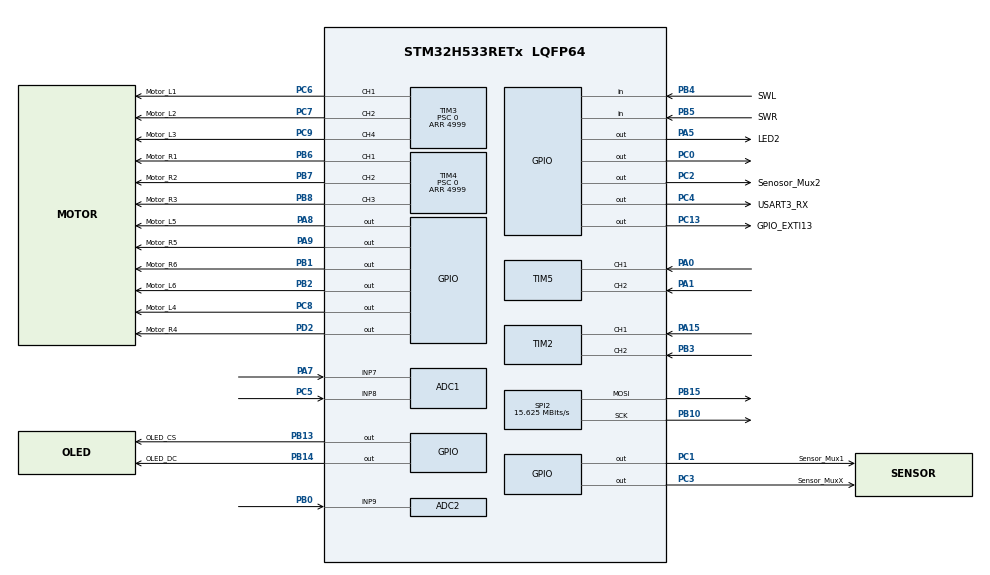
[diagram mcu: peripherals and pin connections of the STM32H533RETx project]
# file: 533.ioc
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ADC1.Channel-0\#ChannelRegularConversion=ADC_CHANNEL_7
ADC1.Channel-1\#ChannelRegularConversion=ADC_CHANNEL_7
ADC1.Channel-2\#ChannelRegularConversion=ADC_CHANNEL_8
ADC1.DiscontinuousConvMode=ENABLE
ADC1.MonitoredBy-0\#ChannelRegularConversion=__NULL
ADC1.MonitoredBy-1\#ChannelRegularConversion=__NULL
ADC1.MonitoredBy-2\#ChannelRegularConversion=__NULL
ADC1.NbrOfConversion=3
ADC1.NbrOfConversionFlag=1
ADC1.NbrOfDiscConversion=1
ADC1.OffsetNumber-0\#ChannelRegularConversion=ADC_OFFSET_NONE
ADC1.OffsetNumber-1\#ChannelRegularConversion=ADC_OFFSET_NONE
ADC1.OffsetNumber-2\#ChannelRegularConversion=ADC_OFFSET_NONE
ADC1.Overrun=ADC_OVR_DATA_OVERWRITTEN
ADC1.Rank-0\#ChannelRegularConversion=1
ADC1.Rank-1\#ChannelRegularConversion=2
ADC1.Rank-2\#ChannelRegularConversion=3
ADC1.SamplingTime-0\#ChannelRegularConversion=ADC_SAMPLETIME_2CYCLES_5
ADC1.SamplingTime-1\#ChannelRegularConversion=ADC_SAMPLETIME_2CYCLES_5
ADC1.SamplingTime-2\#ChannelRegularConversion=ADC_SAMPLETIME_2CYCLES_5
ADC1.master=1
ADC2.Channel-0\#ChannelRegularConversion=ADC_CHANNEL_9
ADC2.MonitoredBy-0\#ChannelRegularConversion=__NULL
ADC2.NbrOfConversionFlag=1
ADC2.OffsetNumber-0\#ChannelRegularConversion=ADC_OFFSET_NONE
ADC2.Rank-0\#ChannelRegularConversion=1
ADC2.SamplingTime-0\#ChannelRegularConversion=ADC_SAMPLETIME_2CYCLES_5
BOOTPATH.BootPathName=LEGACY
BOOTPATH.UserSelectedBootPath=LEGACY
CORTEX_M33_NS.userName=CORTEX_M33
FLASH.OB_EDATA1_active=false
FLASH.advanced_settings=false
Mcu.Family=STM32H5
Mcu.Name=STM32H533RETx
Mcu.Package=LQFP64
NVIC.PriorityGroup=NVIC_PRIORITYGROUP_4
NVIC.TIM3_IRQn=true\:0\:0\:false\:false\:true\:true\:true\:true
NVIC.TIM4_IRQn=true\:0\:0\:false\:false\:true\:true\:true\:true
NVIC.TIM6_IRQn=true\:0\:0\:false\:false\:true\:true\:true\:true
NVIC.TIM7_IRQn=true\:0\:0\:false\:false\:true\:true\:true\:true
PA0.Signal=S_TIM5_CH1
PA1.Signal=S_TIM5_CH2
PA15(JTDI).Signal=S_TIM2_CH1
PA5.GPIO_Label=LED2
PA5.Signal=GPIO_Output
PA7.Signal=ADCx_INP7
PA8.GPIO_Label=Motor_L5
PA8.Signal=GPIO_Output
PA9.GPIO_Label=Motor_R5
PA9.Signal=GPIO_Output
PB0.Signal=ADCx_INP9
PB1.GPIO_Label=Motor_R6
PB1.Signal=GPIO_Output
PB10.Mode=TX_Only_Simplex_Unidirect_Master
PB10.Signal=SPI2_SCK
PB13.GPIO_Label=OLED_CS
PB13.Signal=GPIO_Output
PB14.GPIO_Label=OLED_DC
PB14.Signal=GPIO_Output
PB15.Mode=TX_Only_Simplex_Unidirect_Master
PB15.Signal=SPI2_MOSI
PB2.GPIO_Label=Motor_L6
PB2.Signal=GPIO_Output
PB3(JTDO/TRACESWO).Signal=S_TIM2_CH2
PB4(NJTRST).GPIO_Label=SWL
PB4(NJTRST).GPIO_PuPd=GPIO_PULLUP
PB4(NJTRST).Signal=GPIO_Input
PB5.GPIO_Label=SWR
PB5.GPIO_PuPd=GPIO_PULLUP
PB5.Signal=GPIO_Input
PB6.GPIO_Label=Motor_R1
PB6.Signal=S_TIM4_CH1
PB7.GPIO_Label=Motor_R2
PB7.Signal=S_TIM4_CH2
PB8.GPIO_Label=Motor_R3
PB8.Signal=S_TIM4_CH3
PC0.Signal=GPIO_Output
PC1.GPIO_Label=Sensor_Mux1
PC1.Signal=GPIO_Output
PC13.GPIO_Label=GPIO_EXTI13
PC13.Signal=GPIO_Output
PC14-OSC32_IN(OSC32_IN).Mode=LSE-External-Oscillator
PC14-OSC32_IN(OSC32_IN).Signal=RCC_OSC32_IN
PC15-OSC32_OUT(OSC32_OUT).Mode=LSE-External-Oscillator
PC15-OSC32_OUT(OSC32_OUT).Signal=RCC_OSC32_OUT
PC2.GPIO_Label=Senosor_Mux2
PC2.Signal=GPIO_Output
PC3.GPIO_Label=Sensor_MuxX
PC3.Signal=GPIO_Output
PC4.GPIO_Label=USART3_RX
PC4.Signal=GPIO_Output
PC5.Signal=ADCx_INP8
PC6.GPIO_Label=Motor_L1
PC6.Signal=S_TIM3_CH1
PC7.GPIO_Label=Motor_L2
PC7.Signal=S_TIM3_CH2
PC8.GPIO_Label=Motor_L4
PC8.Signal=GPIO_Output
PC9.GPIO_Label=Motor_L3
PC9.Signal=S_TIM3_CH4
PD2.GPIO_Label=Motor_R4
PD2.Signal=GPIO_Output
PH0-OSC_IN(PH0).Mode=HSE-External-Oscillator
PH0-OSC_IN(PH0).Signal=RCC_OSC_IN
PH1-OSC_OUT(PH1).Mode=HSE-External-Oscillator
PH1-OSC_OUT(PH1).Signal=RCC_OSC_OUT
ProjectManager.HeapSize=0x200
ProjectManager.StackSize=0x400
ProjectManager.TargetToolchain=STM32CubeIDE
RCC.ADCCLockSelection=RCC_ADCDACCLKSOURCE_HSE
RCC.ADCFreq_Value=25000000
RCC.AHBFreq_Value=250000000
RCC.APB1Freq_Value=250000000
RCC.APB1TimFreq_Value=250000000
RCC.APB2Freq_Value=250000000
RCC.APB2TimFreq_Value=250000000
RCC.APB3Freq_Value=250000000
RCC.CSI_VALUE=4000000
RCC.CortexFreq_Value=250000000
RCC.EPOD_VALUE=4000000
RCC.HCLKFreq_Value=250000000
RCC.HSE_VALUE=25000000
RCC.HSI48_VALUE=48000000
RCC.HSI_VALUE=64000000
RCC.LSIRC_VALUE=32000
RCC.PLLFRACN=0
RCC.PLLN=125
RCC.SYSCLKFreq_VALUE=250000000
RCC.SYSCLKSource=RCC_SYSCLKSOURCE_PLLCLK
RCC.USBFreq_Value=48000000
RCC.VCOOutputFreq_Value=500000000
SH.ADCx_INP7.0=ADC1_INP7,IN7-Single-Ended
SH.ADCx_INP8.0=ADC1_INP8,IN8-Single-Ended
SH.ADCx_INP9.0=ADC2_INP9,IN9-Single-Ended
SH.S_TIM2_CH1.0=TIM2_CH1,Encoder_Interface
SH.S_TIM2_CH2.0=TIM2_CH2,Encoder_Interface
SH.S_TIM3_CH1.0=TIM3_CH1,PWM Generation1 CH1
SH.S_TIM3_CH2.0=TIM3_CH2,PWM Generation2 CH2
SH.S_TIM3_CH4.0=TIM3_CH4,PWM Generation4 CH4
SH.S_TIM4_CH1.0=TIM4_CH1,PWM Generation1 CH1
SH.S_TIM4_CH2.0=TIM4_CH2,PWM Generation2 CH2
SH.S_TIM4_CH3.0=TIM4_CH3,PWM Generation3 CH3
SH.S_TIM5_CH1.0=TIM5_CH1,Encoder_Interface
SH.S_TIM5_CH2.0=TIM5_CH2,Encoder_Interface
SPI2.BaudRatePrescaler=SPI_BAUDRATEPRESCALER_16
SPI2.CalculateBaudRate=15.625 MBits/s
SPI2.DataSize=SPI_DATASIZE_8BIT
SPI2.Direction=SPI_DIRECTION_2LINES_TXONLY
SPI2.Mode=SPI_MODE_MASTER
SPI2.VirtualType=VM_MASTER
TIM1.Prescaler=249
TIM3.Channel-PWM\ Generation1\ CH1=TIM_CHANNEL_1
TIM3.Channel-PWM\ Generation2\ CH2=TIM_CHANNEL_2
TIM3.Channel-PWM\ Generation4\ CH4=TIM_CHANNEL_4
TIM3.PeriodNoDither=4999
TIM3.Prescaler=0
TIM4.Channel-PWM\ Generation1\ CH1=TIM_CHANNEL_1
TIM4.Channel-PWM\ Generation2\ CH2=TIM_CHANNEL_2
TIM4.Channel-PWM\ Generation3\ CH3=TIM_CHANNEL_3
TIM4.PeriodNoDither=4999
TIM4.Prescaler=0
TIM6.PeriodNoDither=7999
TIM7.PeriodNoDither=499
TIM7.Prescaler=249
VP_BOOTPATH_VS_BOOTPATH.Mode=BP_Activate
VP_CORTEX_M33_NS_VS_Hclk.Mode=Hclk_Mode
VP_FLASH_SIG_Activate_FlashIP.Mode=Activate_FlashIP
VP_ICACHE_VS_ICACHE.Mode=DefaultMode
VP_MEMORYMAP_VS_MEMORYMAP.Mode=CurAppReg
VP_PWR_VS_DBSignals.Mode=DisableDeadBatterySignals
VP_PWR_VS_LPOM.Mode=PowerOptimisation
VP_PWR_VS_SECSignals.Mode=Security/Privilege
VP_TIM1_VS_ClockSourceINT.Mode=Internal
VP_TIM3_VS_ClockSourceINT.Mode=Internal
VP_TIM4_VS_ClockSourceINT.Mode=Internal
VP_TIM6_VS_ClockSourceINT.Mode=Enable_Timer
VP_TIM7_VS_ClockSourceINT.Mode=Enable_Timer
board=custom

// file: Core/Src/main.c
/* USER CODE BEGIN Header */
/**
  ******************************************************************************
  * @file           : main.c
  * @brief          : Main program body
  ******************************************************************************
  * @attention
  *
  * Copyright (c) 2025 STMicroelectronics.
  * All rights reserved.
  *
  * This software is licensed under terms that can be found in the LICENSE file
  * in the root directory of this software component.
  * If no LICENSE file comes with this software, it is provided AS-IS.
  *
  ******************************************************************************
  */
/* USER CODE END Header */
#include "main.h"

/* USER CODE BEGIN Includes */
#include "init.h"

/* USER CODE END Includes */

void SystemClock_Config(void);
static void MX_GPIO_Init(void);
static void MX_TIM1_Init(void);
static void MX_TIM6_Init(void);
static void MX_TIM3_Init(void);
static void MX_TIM4_Init(void);
static void MX_TIM2_Init(void);
static void MX_TIM5_Init(void);
static void MX_TIM7_Init(void);
static void MX_ADC1_Init(void);
static void MX_ADC2_Init(void);
static void MX_SPI2_Init(void);
static void MX_ICACHE_Init(void);
static void MX_FLASH_Init(void);

int main(void)
{

  /* MCU Configuration--------------------------------------------------------*/

  /* Reset of all peripherals, Initializes the Flash interface and the Systick. */
  HAL_Init();

  /** Disable the internal Pull-Up in Dead Battery pins of UCPD peripheral
  */
  LL_PWR_DisableUCPDDeadBattery();

  /* Configure the system clock */
  SystemClock_Config();

  /* Initialize all configured peripherals */
  MX_GPIO_Init();
  MX_TIM1_Init();
  MX_TIM6_Init();
  MX_TIM3_Init();
  MX_TIM4_Init();
  MX_TIM2_Init();
  MX_TIM5_Init();
  MX_TIM7_Init();
  MX_ADC1_Init();
  MX_ADC2_Init();
  MX_SPI2_Init();
  MX_ICACHE_Init();
  MX_FLASH_Init();

  /* Infinite loop */
  while (1)
  {

    /* USER CODE BEGIN 3 */
	  Init();
  }
  /* USER CODE END 3 */
}

void SystemClock_Config(void)
{
  LL_FLASH_SetLatency(LL_FLASH_LATENCY_5);
  while(LL_FLASH_GetLatency()!= LL_FLASH_LATENCY_5)
  {
  }

  LL_PWR_SetRegulVoltageScaling(LL_PWR_REGU_VOLTAGE_SCALE0);
  while (LL_PWR_IsActiveFlag_VOS() == 0)
  {
  }
  LL_RCC_HSE_Enable();

   /* Wait till HSE is ready */
  while(LL_RCC_HSE_IsReady() != 1)
  {
  }

  LL_RCC_CSI_Enable();

   /* Wait till CSI is ready */
  while(LL_RCC_CSI_IsReady() != 1)
  {
  }

  LL_RCC_CSI_SetCalibTrimming(32);
  LL_RCC_PLL1_SetSource(LL_RCC_PLL1SOURCE_CSI);
  LL_RCC_PLL1_SetVCOInputRange(LL_RCC_PLLINPUTRANGE_4_8);
  LL_RCC_PLL1_SetVCOOutputRange(LL_RCC_PLLVCORANGE_WIDE);
  LL_RCC_PLL1_SetM(1);
  LL_RCC_PLL1_SetN(125);
  LL_RCC_PLL1_SetP(2);
  LL_RCC_PLL1_SetQ(2);
  LL_RCC_PLL1_SetR(2);
  LL_RCC_PLL1Q_Enable();
  LL_RCC_PLL1P_Enable();
  LL_RCC_PLL1_Enable();

   /* Wait till PLL is ready */
  while(LL_RCC_PLL1_IsReady() != 1)
  {
  }

  LL_RCC_SetSysClkSource(LL_RCC_SYS_CLKSOURCE_PLL1);

   /* Wait till System clock is ready */
  while(LL_RCC_GetSysClkSource() != LL_RCC_SYS_CLKSOURCE_STATUS_PLL1)
  {
  }

  LL_RCC_SetAHBPrescaler(LL_RCC_SYSCLK_DIV_1);
  LL_RCC_SetAPB1Prescaler(LL_RCC_APB1_DIV_1);
  LL_RCC_SetAPB2Prescaler(LL_RCC_APB2_DIV_1);
  LL_RCC_SetAPB3Prescaler(LL_RCC_APB3_DIV_1);
  LL_SetSystemCoreClock(250000000);

   /* Update the time base */
  if (HAL_InitTick (TICK_INT_PRIORITY) != HAL_OK)
  {
    Error_Handler();
  }
}

static void MX_ADC1_Init(void)
{

  LL_ADC_CommonInitTypeDef ADC_CommonInitStruct = {0};
  LL_ADC_InitTypeDef ADC_InitStruct = {0};
  LL_ADC_REG_InitTypeDef ADC_REG_InitStruct = {0};

  LL_GPIO_InitTypeDef GPIO_InitStruct = {0};

  LL_RCC_SetADCDACClockSource(LL_RCC_ADCDAC_CLKSOURCE_HSE);

  /* Peripheral clock enable */
  LL_AHB2_GRP1_EnableClock(LL_AHB2_GRP1_PERIPH_ADC);

  LL_AHB2_GRP1_EnableClock(LL_AHB2_GRP1_PERIPH_GPIOA);
  LL_AHB2_GRP1_EnableClock(LL_AHB2_GRP1_PERIPH_GPIOC);
  /**ADC1 GPIO Configuration
  PA7   ------> ADC1_INP7
  PC5   ------> ADC1_INP8
  */
  GPIO_InitStruct.Pin = LL_GPIO_PIN_7;
  GPIO_InitStruct.Mode = LL_GPIO_MODE_ANALOG;
  GPIO_InitStruct.Pull = LL_GPIO_PULL_NO;
  LL_GPIO_Init(GPIOA, &GPIO_InitStruct);

  GPIO_InitStruct.Pin = LL_GPIO_PIN_5;
  GPIO_InitStruct.Mode = LL_GPIO_MODE_ANALOG;
  GPIO_InitStruct.Pull = LL_GPIO_PULL_NO;
  LL_GPIO_Init(GPIOC, &GPIO_InitStruct);

  /** Configure the ADC multi-mode
  */
  ADC_CommonInitStruct.CommonClock = LL_ADC_CLOCK_ASYNC_DIV1;
  ADC_CommonInitStruct.Multimode = LL_ADC_MULTI_INDEPENDENT;
  LL_ADC_CommonInit(__LL_ADC_COMMON_INSTANCE(ADC1), &ADC_CommonInitStruct);

  /** Common config
  */
  ADC_InitStruct.Resolution = LL_ADC_RESOLUTION_12B;
  ADC_InitStruct.DataAlignment = LL_ADC_DATA_ALIGN_RIGHT;
  ADC_InitStruct.LowPowerMode = LL_ADC_LP_MODE_NONE;
  LL_ADC_Init(ADC1, &ADC_InitStruct);
  ADC_REG_InitStruct.TriggerSource = LL_ADC_REG_TRIG_SOFTWARE;
  ADC_REG_InitStruct.SequencerLength = LL_ADC_REG_SEQ_SCAN_ENABLE_3RANKS;
  ADC_REG_InitStruct.SequencerDiscont = LL_ADC_REG_SEQ_DISCONT_1RANK;
  ADC_REG_InitStruct.ContinuousMode = LL_ADC_REG_CONV_SINGLE;
  ADC_REG_InitStruct.Overrun = LL_ADC_REG_OVR_DATA_OVERWRITTEN;
  LL_ADC_REG_Init(ADC1, &ADC_REG_InitStruct);
  LL_ADC_REG_SetSamplingMode(ADC1, LL_ADC_REG_SAMPLING_MODE_NORMAL);

  /* Disable ADC deep power down (enabled by default after reset state) */
  LL_ADC_DisableDeepPowerDown(ADC1);
  /* Enable ADC internal voltage regulator */
  LL_ADC_EnableInternalRegulator(ADC1);
  /* Delay for ADC internal voltage regulator stabilization. */
  /* Compute number of CPU cycles to wait for, from delay in us. */
  /* Note: Variable divided by 2 to compensate partially */
  /* CPU processing cycles (depends on compilation optimization). */
  /* Note: If system core clock frequency is below 200kHz, wait time */
  /* is only a few CPU processing cycles. */
  uint32_t wait_loop_index;
  wait_loop_index = ((LL_ADC_DELAY_INTERNAL_REGUL_STAB_US * (SystemCoreClock / (100000 * 2))) / 10);
  while(wait_loop_index != 0)
  {
    wait_loop_index--;
  }

  /** Configure Regular Channel
  */
  LL_ADC_REG_SetSequencerRanks(ADC1, LL_ADC_REG_RANK_1, LL_ADC_CHANNEL_7);
  LL_ADC_SetChannelSamplingTime(ADC1, LL_ADC_CHANNEL_7, LL_ADC_SAMPLINGTIME_2CYCLES_5);
  LL_ADC_SetChannelSingleDiff(ADC1, LL_ADC_CHANNEL_7, LL_ADC_SINGLE_ENDED);

  /** Configure Regular Channel
  */
  LL_ADC_REG_SetSequencerRanks(ADC1, LL_ADC_REG_RANK_2, LL_ADC_CHANNEL_7);
  LL_ADC_SetChannelSamplingTime(ADC1, LL_ADC_CHANNEL_7, LL_ADC_SAMPLINGTIME_2CYCLES_5);
  LL_ADC_SetChannelSingleDiff(ADC1, LL_ADC_CHANNEL_7, LL_ADC_SINGLE_ENDED);

  /** Configure Regular Channel
  */
  LL_ADC_REG_SetSequencerRanks(ADC1, LL_ADC_REG_RANK_3, LL_ADC_CHANNEL_8);
  LL_ADC_SetChannelSamplingTime(ADC1, LL_ADC_CHANNEL_8, LL_ADC_SAMPLINGTIME_2CYCLES_5);
  LL_ADC_SetChannelSingleDiff(ADC1, LL_ADC_CHANNEL_8, LL_ADC_SINGLE_ENDED);

}

static void MX_ADC2_Init(void)
{

  LL_ADC_CommonInitTypeDef ADC_CommonInitStruct = {0};
  LL_ADC_InitTypeDef ADC_InitStruct = {0};
  LL_ADC_REG_InitTypeDef ADC_REG_InitStruct = {0};

  LL_GPIO_InitTypeDef GPIO_InitStruct = {0};

  LL_RCC_SetADCDACClockSource(LL_RCC_ADCDAC_CLKSOURCE_HSE);

  /* Peripheral clock enable */
  LL_AHB2_GRP1_EnableClock(LL_AHB2_GRP1_PERIPH_ADC);

  LL_AHB2_GRP1_EnableClock(LL_AHB2_GRP1_PERIPH_GPIOB);
  /**ADC2 GPIO Configuration
  PB0   ------> ADC2_INP9
  */
  GPIO_InitStruct.Pin = LL_GPIO_PIN_0;
  GPIO_InitStruct.Mode = LL_GPIO_MODE_ANALOG;
  GPIO_InitStruct.Pull = LL_GPIO_PULL_NO;
  LL_GPIO_Init(GPIOB, &GPIO_InitStruct);

  /** Configure the ADC multi-mode
  */
  ADC_CommonInitStruct.CommonClock = LL_ADC_CLOCK_ASYNC_DIV1;
  ADC_CommonInitStruct.Multimode = LL_ADC_MULTI_INDEPENDENT;
  LL_ADC_CommonInit(__LL_ADC_COMMON_INSTANCE(ADC2), &ADC_CommonInitStruct);

  /** Common config
  */
  ADC_InitStruct.Resolution = LL_ADC_RESOLUTION_12B;
  ADC_InitStruct.DataAlignment = LL_ADC_DATA_ALIGN_RIGHT;
  ADC_InitStruct.LowPowerMode = LL_ADC_LP_MODE_NONE;
  LL_ADC_Init(ADC2, &ADC_InitStruct);
  ADC_REG_InitStruct.TriggerSource = LL_ADC_REG_TRIG_SOFTWARE;
  ADC_REG_InitStruct.SequencerLength = LL_ADC_REG_SEQ_SCAN_DISABLE;
  ADC_REG_InitStruct.SequencerDiscont = LL_ADC_REG_SEQ_DISCONT_DISABLE;
  ADC_REG_InitStruct.ContinuousMode = LL_ADC_REG_CONV_SINGLE;
  ADC_REG_InitStruct.Overrun = LL_ADC_REG_OVR_DATA_PRESERVED;
  LL_ADC_REG_Init(ADC2, &ADC_REG_InitStruct);
  LL_ADC_REG_SetSamplingMode(ADC2, LL_ADC_REG_SAMPLING_MODE_NORMAL);

  /* Disable ADC deep power down (enabled by default after reset state) */
  LL_ADC_DisableDeepPowerDown(ADC2);
  /* Enable ADC internal voltage regulator */
  LL_ADC_EnableInternalRegulator(ADC2);
  /* Delay for ADC internal voltage regulator stabilization. */
  /* Compute number of CPU cycles to wait for, from delay in us. */
  /* Note: Variable divided by 2 to compensate partially */
  /* CPU processing cycles (depends on compilation optimization). */
  /* Note: If system core clock frequency is below 200kHz, wait time */
  /* is only a few CPU processing cycles. */
  uint32_t wait_loop_index;
  wait_loop_index = ((LL_ADC_DELAY_INTERNAL_REGUL_STAB_US * (SystemCoreClock / (100000 * 2))) / 10);
  while(wait_loop_index != 0)
  {
    wait_loop_index--;
  }

  /** Configure Regular Channel
  */
  LL_ADC_REG_SetSequencerRanks(ADC2, LL_ADC_REG_RANK_1, LL_ADC_CHANNEL_9);
  LL_ADC_SetChannelSamplingTime(ADC2, LL_ADC_CHANNEL_9, LL_ADC_SAMPLINGTIME_2CYCLES_5);
  LL_ADC_SetChannelSingleDiff(ADC2, LL_ADC_CHANNEL_9, LL_ADC_SINGLE_ENDED);

}

static void MX_FLASH_Init(void)
{

  if (HAL_FLASH_Unlock() != HAL_OK)
  {
    Error_Handler();
  }
  if (HAL_FLASH_Lock() != HAL_OK)
  {
    Error_Handler();
  }

}

static void MX_ICACHE_Init(void)
{

  /** Enable instruction cache (default 2-ways set associative cache)
  */
  LL_ICACHE_Enable();

}

static void MX_SPI2_Init(void)
{

  LL_SPI_InitTypeDef SPI_InitStruct = {0};

  LL_GPIO_InitTypeDef GPIO_InitStruct = {0};

  LL_RCC_SetSPIClockSource(LL_RCC_SPI2_CLKSOURCE_PLL1Q);

  /* Peripheral clock enable */
  LL_APB1_GRP1_EnableClock(LL_APB1_GRP1_PERIPH_SPI2);

  LL_AHB2_GRP1_EnableClock(LL_AHB2_GRP1_PERIPH_GPIOB);
  /**SPI2 GPIO Configuration
  PB10   ------> SPI2_SCK
  PB15   ------> SPI2_MOSI
  */
  GPIO_InitStruct.Pin = LL_GPIO_PIN_10|LL_GPIO_PIN_15;
  GPIO_InitStruct.Mode = LL_GPIO_MODE_ALTERNATE;
  GPIO_InitStruct.Speed = LL_GPIO_SPEED_FREQ_LOW;
  GPIO_InitStruct.OutputType = LL_GPIO_OUTPUT_PUSHPULL;
  GPIO_InitStruct.Pull = LL_GPIO_PULL_NO;
  GPIO_InitStruct.Alternate = LL_GPIO_AF_5;
  LL_GPIO_Init(GPIOB, &GPIO_InitStruct);

  /* SPI2 parameter configuration*/
  SPI_InitStruct.TransferDirection = LL_SPI_SIMPLEX_TX;
  SPI_InitStruct.Mode = LL_SPI_MODE_MASTER;
  SPI_InitStruct.DataWidth = LL_SPI_DATAWIDTH_8BIT;
  SPI_InitStruct.ClockPolarity = LL_SPI_POLARITY_LOW;
  SPI_InitStruct.ClockPhase = LL_SPI_PHASE_1EDGE;
  SPI_InitStruct.NSS = LL_SPI_NSS_SOFT;
  SPI_InitStruct.BaudRate = LL_SPI_BAUDRATEPRESCALER_DIV16;
  SPI_InitStruct.BitOrder = LL_SPI_MSB_FIRST;
  SPI_InitStruct.CRCCalculation = LL_SPI_CRCCALCULATION_DISABLE;
  SPI_InitStruct.CRCPoly = 0x7;
  LL_SPI_Init(SPI2, &SPI_InitStruct);
  LL_SPI_SetStandard(SPI2, LL_SPI_PROTOCOL_MOTOROLA);
  LL_SPI_EnableNSSPulseMgt(SPI2);

}

static void MX_TIM1_Init(void)
{

  LL_TIM_InitTypeDef TIM_InitStruct = {0};

  /* Peripheral clock enable */
  LL_APB2_GRP1_EnableClock(LL_APB2_GRP1_PERIPH_TIM1);

  TIM_InitStruct.Prescaler = 249;
  TIM_InitStruct.CounterMode = LL_TIM_COUNTERMODE_UP;
  TIM_InitStruct.Autoreload = 65535;
  TIM_InitStruct.ClockDivision = LL_TIM_CLOCKDIVISION_DIV1;
  TIM_InitStruct.RepetitionCounter = 0;
  LL_TIM_Init(TIM1, &TIM_InitStruct);
  LL_TIM_DisableARRPreload(TIM1);
  LL_TIM_SetClockSource(TIM1, LL_TIM_CLOCKSOURCE_INTERNAL);
  LL_TIM_SetTriggerOutput(TIM1, LL_TIM_TRGO_RESET);
  LL_TIM_SetTriggerOutput2(TIM1, LL_TIM_TRGO2_RESET);
  LL_TIM_DisableMasterSlaveMode(TIM1);

}

static void MX_TIM2_Init(void)
{

  LL_TIM_InitTypeDef TIM_InitStruct = {0};

  LL_GPIO_InitTypeDef GPIO_InitStruct = {0};

  /* Peripheral clock enable */
  LL_APB1_GRP1_EnableClock(LL_APB1_GRP1_PERIPH_TIM2);

  LL_AHB2_GRP1_EnableClock(LL_AHB2_GRP1_PERIPH_GPIOA);
  LL_AHB2_GRP1_EnableClock(LL_AHB2_GRP1_PERIPH_GPIOB);
  /**TIM2 GPIO Configuration
  PA15(JTDI)   ------> TIM2_CH1
  PB3(JTDO/TRACESWO)   ------> TIM2_CH2
  */
  GPIO_InitStruct.Pin = LL_GPIO_PIN_15;
  GPIO_InitStruct.Mode = LL_GPIO_MODE_ALTERNATE;
  GPIO_InitStruct.Speed = LL_GPIO_SPEED_FREQ_LOW;
  GPIO_InitStruct.OutputType = LL_GPIO_OUTPUT_PUSHPULL;
  GPIO_InitStruct.Pull = LL_GPIO_PULL_NO;
  GPIO_InitStruct.Alternate = LL_GPIO_AF_1;
  LL_GPIO_Init(GPIOA, &GPIO_InitStruct);

  GPIO_InitStruct.Pin = LL_GPIO_PIN_3;
  GPIO_InitStruct.Mode = LL_GPIO_MODE_ALTERNATE;
  GPIO_InitStruct.Speed = LL_GPIO_SPEED_FREQ_LOW;
  GPIO_InitStruct.OutputType = LL_GPIO_OUTPUT_PUSHPULL;
  GPIO_InitStruct.Pull = LL_GPIO_PULL_NO;
  GPIO_InitStruct.Alternate = LL_GPIO_AF_1;
  LL_GPIO_Init(GPIOB, &GPIO_InitStruct);

  TIM_InitStruct.Prescaler = 0;
  TIM_InitStruct.CounterMode = LL_TIM_COUNTERMODE_UP;
  TIM_InitStruct.Autoreload = 4294967295;
  TIM_InitStruct.ClockDivision = LL_TIM_CLOCKDIVISION_DIV1;
  LL_TIM_Init(TIM2, &TIM_InitStruct);
  LL_TIM_DisableARRPreload(TIM2);
  LL_TIM_SetEncoderMode(TIM2, LL_TIM_ENCODERMODE_X2_TI1);
  LL_TIM_IC_SetActiveInput(TIM2, LL_TIM_CHANNEL_CH1, LL_TIM_ACTIVEINPUT_DIRECTTI);
  LL_TIM_IC_SetPrescaler(TIM2, LL_TIM_CHANNEL_CH1, LL_TIM_ICPSC_DIV1);
  LL_TIM_IC_SetFilter(TIM2, LL_TIM_CHANNEL_CH1, LL_TIM_IC_FILTER_FDIV1);
  LL_TIM_IC_SetPolarity(TIM2, LL_TIM_CHANNEL_CH1, LL_TIM_IC_POLARITY_RISING);
  LL_TIM_IC_SetActiveInput(TIM2, LL_TIM_CHANNEL_CH2, LL_TIM_ACTIVEINPUT_DIRECTTI);
  LL_TIM_IC_SetPrescaler(TIM2, LL_TIM_CHANNEL_CH2, LL_TIM_ICPSC_DIV1);
  LL_TIM_IC_SetFilter(TIM2, LL_TIM_CHANNEL_CH2, LL_TIM_IC_FILTER_FDIV1);
  LL_TIM_IC_SetPolarity(TIM2, LL_TIM_CHANNEL_CH2, LL_TIM_IC_POLARITY_RISING);
  LL_TIM_SetTriggerOutput(TIM2, LL_TIM_TRGO_RESET);
  LL_TIM_DisableMasterSlaveMode(TIM2);

}

static void MX_TIM3_Init(void)
{

  LL_TIM_InitTypeDef TIM_InitStruct = {0};
  LL_TIM_OC_InitTypeDef TIM_OC_InitStruct = {0};

  LL_GPIO_InitTypeDef GPIO_InitStruct = {0};

  /* Peripheral clock enable */
  LL_APB1_GRP1_EnableClock(LL_APB1_GRP1_PERIPH_TIM3);

  /* TIM3 interrupt Init */
  NVIC_SetPriority(TIM3_IRQn, NVIC_EncodePriority(NVIC_GetPriorityGrouping(),0, 0));
  NVIC_EnableIRQ(TIM3_IRQn);

  TIM_InitStruct.Prescaler = 0;
  TIM_InitStruct.CounterMode = LL_TIM_COUNTERMODE_UP;
  TIM_InitStruct.Autoreload = 4999;
  TIM_InitStruct.ClockDivision = LL_TIM_CLOCKDIVISION_DIV1;
  LL_TIM_Init(TIM3, &TIM_InitStruct);
  LL_TIM_DisableARRPreload(TIM3);
  LL_TIM_SetClockSource(TIM3, LL_TIM_CLOCKSOURCE_INTERNAL);
  LL_TIM_OC_EnablePreload(TIM3, LL_TIM_CHANNEL_CH1);
  TIM_OC_InitStruct.OCMode = LL_TIM_OCMODE_PWM1;
  TIM_OC_InitStruct.OCState = LL_TIM_OCSTATE_DISABLE;
  TIM_OC_InitStruct.OCNState = LL_TIM_OCSTATE_DISABLE;
  TIM_OC_InitStruct.CompareValue = 0;
  TIM_OC_InitStruct.OCPolarity = LL_TIM_OCPOLARITY_HIGH;
  LL_TIM_OC_Init(TIM3, LL_TIM_CHANNEL_CH1, &TIM_OC_InitStruct);
  LL_TIM_OC_DisableFast(TIM3, LL_TIM_CHANNEL_CH1);
  LL_TIM_OC_EnablePreload(TIM3, LL_TIM_CHANNEL_CH2);
  LL_TIM_OC_Init(TIM3, LL_TIM_CHANNEL_CH2, &TIM_OC_InitStruct);
  LL_TIM_OC_DisableFast(TIM3, LL_TIM_CHANNEL_CH2);
  LL_TIM_OC_EnablePreload(TIM3, LL_TIM_CHANNEL_CH4);
  LL_TIM_OC_Init(TIM3, LL_TIM_CHANNEL_CH4, &TIM_OC_InitStruct);
  LL_TIM_OC_DisableFast(TIM3, LL_TIM_CHANNEL_CH4);
  LL_TIM_SetTriggerOutput(TIM3, LL_TIM_TRGO_RESET);
  LL_TIM_DisableMasterSlaveMode(TIM3);
  LL_AHB2_GRP1_EnableClock(LL_AHB2_GRP1_PERIPH_GPIOC);
  /**TIM3 GPIO Configuration
  PC6   ------> TIM3_CH1
  PC7   ------> TIM3_CH2
  PC9   ------> TIM3_CH4
  */
  GPIO_InitStruct.Pin = Motor_L1_Pin|Motor_L2_Pin|Motor_L3_Pin;
  GPIO_InitStruct.Mode = LL_GPIO_MODE_ALTERNATE;
  GPIO_InitStruct.Speed = LL_GPIO_SPEED_FREQ_LOW;
  GPIO_InitStruct.OutputType = LL_GPIO_OUTPUT_PUSHPULL;
  GPIO_InitStruct.Pull = LL_GPIO_PULL_NO;
  GPIO_InitStruct.Alternate = LL_GPIO_AF_2;
  LL_GPIO_Init(GPIOC, &GPIO_InitStruct);

}

static void MX_TIM4_Init(void)
{

  LL_TIM_InitTypeDef TIM_InitStruct = {0};
  LL_TIM_OC_InitTypeDef TIM_OC_InitStruct = {0};

  LL_GPIO_InitTypeDef GPIO_InitStruct = {0};

  /* Peripheral clock enable */
  LL_APB1_GRP1_EnableClock(LL_APB1_GRP1_PERIPH_TIM4);

  /* TIM4 interrupt Init */
  NVIC_SetPriority(TIM4_IRQn, NVIC_EncodePriority(NVIC_GetPriorityGrouping(),0, 0));
  NVIC_EnableIRQ(TIM4_IRQn);

  TIM_InitStruct.Prescaler = 0;
  TIM_InitStruct.CounterMode = LL_TIM_COUNTERMODE_UP;
  TIM_InitStruct.Autoreload = 4999;
  TIM_InitStruct.ClockDivision = LL_TIM_CLOCKDIVISION_DIV1;
  LL_TIM_Init(TIM4, &TIM_InitStruct);
  LL_TIM_DisableARRPreload(TIM4);
  LL_TIM_SetClockSource(TIM4, LL_TIM_CLOCKSOURCE_INTERNAL);
  LL_TIM_OC_EnablePreload(TIM4, LL_TIM_CHANNEL_CH1);
  TIM_OC_InitStruct.OCMode = LL_TIM_OCMODE_PWM1;
  TIM_OC_InitStruct.OCState = LL_TIM_OCSTATE_DISABLE;
  TIM_OC_InitStruct.OCNState = LL_TIM_OCSTATE_DISABLE;
  TIM_OC_InitStruct.CompareValue = 0;
  TIM_OC_InitStruct.OCPolarity = LL_TIM_OCPOLARITY_HIGH;
  LL_TIM_OC_Init(TIM4, LL_TIM_CHANNEL_CH1, &TIM_OC_InitStruct);
  LL_TIM_OC_DisableFast(TIM4, LL_TIM_CHANNEL_CH1);
  LL_TIM_OC_EnablePreload(TIM4, LL_TIM_CHANNEL_CH2);
  LL_TIM_OC_Init(TIM4, LL_TIM_CHANNEL_CH2, &TIM_OC_InitStruct);
  LL_TIM_OC_DisableFast(TIM4, LL_TIM_CHANNEL_CH2);
  LL_TIM_OC_EnablePreload(TIM4, LL_TIM_CHANNEL_CH3);
  LL_TIM_OC_Init(TIM4, LL_TIM_CHANNEL_CH3, &TIM_OC_InitStruct);
  LL_TIM_OC_DisableFast(TIM4, LL_TIM_CHANNEL_CH3);
  LL_TIM_SetTriggerOutput(TIM4, LL_TIM_TRGO_RESET);
  LL_TIM_DisableMasterSlaveMode(TIM4);
  LL_AHB2_GRP1_EnableClock(LL_AHB2_GRP1_PERIPH_GPIOB);
  /**TIM4 GPIO Configuration
  PB6   ------> TIM4_CH1
  PB7   ------> TIM4_CH2
  PB8   ------> TIM4_CH3
  */
  GPIO_InitStruct.Pin = Motor_R1_Pin|Motor_R2_Pin|Motor_R3_Pin;
  GPIO_InitStruct.Mode = LL_GPIO_MODE_ALTERNATE;
  GPIO_InitStruct.Speed = LL_GPIO_SPEED_FREQ_LOW;
  GPIO_InitStruct.OutputType = LL_GPIO_OUTPUT_PUSHPULL;
  GPIO_InitStruct.Pull = LL_GPIO_PULL_NO;
  GPIO_InitStruct.Alternate = LL_GPIO_AF_2;
  LL_GPIO_Init(GPIOB, &GPIO_InitStruct);

}

static void MX_TIM5_Init(void)
{

  LL_TIM_InitTypeDef TIM_InitStruct = {0};

  LL_GPIO_InitTypeDef GPIO_InitStruct = {0};

  /* Peripheral clock enable */
  LL_APB1_GRP1_EnableClock(LL_APB1_GRP1_PERIPH_TIM5);

  LL_AHB2_GRP1_EnableClock(LL_AHB2_GRP1_PERIPH_GPIOA);
  /**TIM5 GPIO Configuration
  PA0   ------> TIM5_CH1
  PA1   ------> TIM5_CH2
  */
  GPIO_InitStruct.Pin = LL_GPIO_PIN_0|LL_GPIO_PIN_1;
  GPIO_InitStruct.Mode = LL_GPIO_MODE_ALTERNATE;
  GPIO_InitStruct.Speed = LL_GPIO_SPEED_FREQ_LOW;
  GPIO_InitStruct.OutputType = LL_GPIO_OUTPUT_PUSHPULL;
  GPIO_InitStruct.Pull = LL_GPIO_PULL_NO;
  GPIO_InitStruct.Alternate = LL_GPIO_AF_2;
  LL_GPIO_Init(GPIOA, &GPIO_InitStruct);

  TIM_InitStruct.Prescaler = 0;
  TIM_InitStruct.CounterMode = LL_TIM_COUNTERMODE_UP;
  TIM_InitStruct.Autoreload = 4294967295;
  TIM_InitStruct.ClockDivision = LL_TIM_CLOCKDIVISION_DIV1;
  LL_TIM_Init(TIM5, &TIM_InitStruct);
  LL_TIM_DisableARRPreload(TIM5);
  LL_TIM_SetEncoderMode(TIM5, LL_TIM_ENCODERMODE_X2_TI1);
  LL_TIM_IC_SetActiveInput(TIM5, LL_TIM_CHANNEL_CH1, LL_TIM_ACTIVEINPUT_DIRECTTI);
  LL_TIM_IC_SetPrescaler(TIM5, LL_TIM_CHANNEL_CH1, LL_TIM_ICPSC_DIV1);
  LL_TIM_IC_SetFilter(TIM5, LL_TIM_CHANNEL_CH1, LL_TIM_IC_FILTER_FDIV1);
  LL_TIM_IC_SetPolarity(TIM5, LL_TIM_CHANNEL_CH1, LL_TIM_IC_POLARITY_RISING);
  LL_TIM_IC_SetActiveInput(TIM5, LL_TIM_CHANNEL_CH2, LL_TIM_ACTIVEINPUT_DIRECTTI);
  LL_TIM_IC_SetPrescaler(TIM5, LL_TIM_CHANNEL_CH2, LL_TIM_ICPSC_DIV1);
  LL_TIM_IC_SetFilter(TIM5, LL_TIM_CHANNEL_CH2, LL_TIM_IC_FILTER_FDIV1);
  LL_TIM_IC_SetPolarity(TIM5, LL_TIM_CHANNEL_CH2, LL_TIM_IC_POLARITY_RISING);
  LL_TIM_SetTriggerOutput(TIM5, LL_TIM_TRGO_RESET);
  LL_TIM_DisableMasterSlaveMode(TIM5);

}

static void MX_TIM6_Init(void)
{

  LL_TIM_InitTypeDef TIM_InitStruct = {0};

  /* Peripheral clock enable */
  LL_APB1_GRP1_EnableClock(LL_APB1_GRP1_PERIPH_TIM6);

  /* TIM6 interrupt Init */
  NVIC_SetPriority(TIM6_IRQn, NVIC_EncodePriority(NVIC_GetPriorityGrouping(),0, 0));
  NVIC_EnableIRQ(TIM6_IRQn);

  TIM_InitStruct.Prescaler = 0;
  TIM_InitStruct.CounterMode = LL_TIM_COUNTERMODE_UP;
  TIM_InitStruct.Autoreload = 7999;
  LL_TIM_Init(TIM6, &TIM_InitStruct);
  LL_TIM_DisableARRPreload(TIM6);
  LL_TIM_SetTriggerOutput(TIM6, LL_TIM_TRGO_RESET);
  LL_TIM_DisableMasterSlaveMode(TIM6);

}

static void MX_TIM7_Init(void)
{

  LL_TIM_InitTypeDef TIM_InitStruct = {0};

  /* Peripheral clock enable */
  LL_APB1_GRP1_EnableClock(LL_APB1_GRP1_PERIPH_TIM7);

  /* TIM7 interrupt Init */
  NVIC_SetPriority(TIM7_IRQn, NVIC_EncodePriority(NVIC_GetPriorityGrouping(),0, 0));
  NVIC_EnableIRQ(TIM7_IRQn);

  TIM_InitStruct.Prescaler = 249;
  TIM_InitStruct.CounterMode = LL_TIM_COUNTERMODE_UP;
  TIM_InitStruct.Autoreload = 499;
  LL_TIM_Init(TIM7, &TIM_InitStruct);
  LL_TIM_DisableARRPreload(TIM7);
  LL_TIM_SetTriggerOutput(TIM7, LL_TIM_TRGO_RESET);
  LL_TIM_DisableMasterSlaveMode(TIM7);

}

static void MX_GPIO_Init(void)
{
  LL_GPIO_InitTypeDef GPIO_InitStruct = {0};

  /* GPIO Ports Clock Enable */
  LL_AHB2_GRP1_EnableClock(LL_AHB2_GRP1_PERIPH_GPIOC);
  LL_AHB2_GRP1_EnableClock(LL_AHB2_GRP1_PERIPH_GPIOH);
  LL_AHB2_GRP1_EnableClock(LL_AHB2_GRP1_PERIPH_GPIOA);
  LL_AHB2_GRP1_EnableClock(LL_AHB2_GRP1_PERIPH_GPIOB);
  LL_AHB2_GRP1_EnableClock(LL_AHB2_GRP1_PERIPH_GPIOD);

  /**/
  LL_GPIO_ResetOutputPin(GPIOC, GPIO_EXTI13_Pin|LL_GPIO_PIN_0|Sensor_Mux1_Pin|Senosor_Mux2_Pin
                          |Sensor_MuxX_Pin|USART3_RX_Pin|Motor_L4_Pin);

  /**/
  LL_GPIO_ResetOutputPin(GPIOA, LED2_Pin|Motor_L5_Pin|Motor_R5_Pin);

  /**/
  LL_GPIO_ResetOutputPin(GPIOB, Motor_R6_Pin|Motor_L6_Pin|OLED_CS_Pin|OLED_DC_Pin);

  /**/
  LL_GPIO_ResetOutputPin(Motor_R4_GPIO_Port, Motor_R4_Pin);

  /**/
  GPIO_InitStruct.Pin = GPIO_EXTI13_Pin|LL_GPIO_PIN_0|Sensor_Mux1_Pin|Senosor_Mux2_Pin
                          |Sensor_MuxX_Pin|USART3_RX_Pin|Motor_L4_Pin;
  GPIO_InitStruct.Mode = LL_GPIO_MODE_OUTPUT;
  GPIO_InitStruct.Speed = LL_GPIO_SPEED_FREQ_LOW;
  GPIO_InitStruct.OutputType = LL_GPIO_OUTPUT_PUSHPULL;
  GPIO_InitStruct.Pull = LL_GPIO_PULL_NO;
  LL_GPIO_Init(GPIOC, &GPIO_InitStruct);

  /**/
  GPIO_InitStruct.Pin = LED2_Pin|Motor_L5_Pin|Motor_R5_Pin;
  GPIO_InitStruct.Mode = LL_GPIO_MODE_OUTPUT;
  GPIO_InitStruct.Speed = LL_GPIO_SPEED_FREQ_LOW;
  GPIO_InitStruct.OutputType = LL_GPIO_OUTPUT_PUSHPULL;
  GPIO_InitStruct.Pull = LL_GPIO_PULL_NO;
  LL_GPIO_Init(GPIOA, &GPIO_InitStruct);

  /**/
  GPIO_InitStruct.Pin = Motor_R6_Pin|Motor_L6_Pin|OLED_CS_Pin|OLED_DC_Pin;
  GPIO_InitStruct.Mode = LL_GPIO_MODE_OUTPUT;
  GPIO_InitStruct.Speed = LL_GPIO_SPEED_FREQ_LOW;
  GPIO_InitStruct.OutputType = LL_GPIO_OUTPUT_PUSHPULL;
  GPIO_InitStruct.Pull = LL_GPIO_PULL_NO;
  LL_GPIO_Init(GPIOB, &GPIO_InitStruct);

  /**/
  GPIO_InitStruct.Pin = Motor_R4_Pin;
  GPIO_InitStruct.Mode = LL_GPIO_MODE_OUTPUT;
  GPIO_InitStruct.Speed = LL_GPIO_SPEED_FREQ_LOW;
  GPIO_InitStruct.OutputType = LL_GPIO_OUTPUT_PUSHPULL;
  GPIO_InitStruct.Pull = LL_GPIO_PULL_NO;
  LL_GPIO_Init(Motor_R4_GPIO_Port, &GPIO_InitStruct);

  /**/
  GPIO_InitStruct.Pin = SWL_Pin|SWR_Pin;
  GPIO_InitStruct.Mode = LL_GPIO_MODE_INPUT;
  GPIO_InitStruct.Pull = LL_GPIO_PULL_UP;
  LL_GPIO_Init(GPIOB, &GPIO_InitStruct);

}

void Error_Handler(void)
{
  __disable_irq();
  while (1)
  {
  }
}
